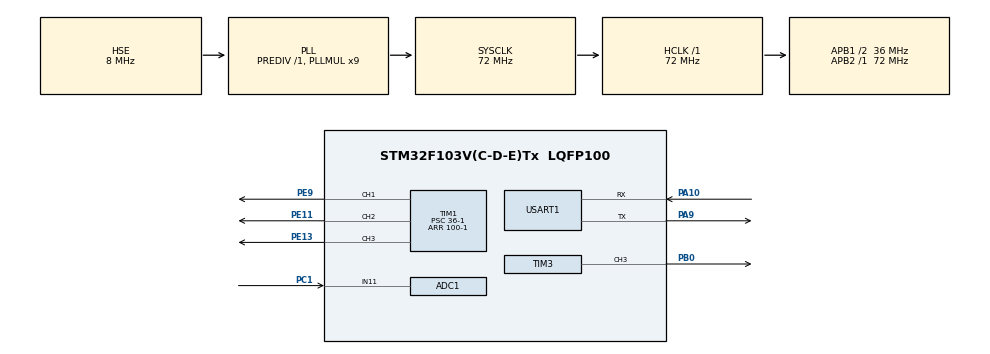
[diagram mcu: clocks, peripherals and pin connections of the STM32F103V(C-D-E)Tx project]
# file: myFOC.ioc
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ADC1.Channel-0\#ChannelRegularConversion=ADC_CHANNEL_11
ADC1.ContinuousConvMode=ENABLE
ADC1.NbrOfConversionFlag=1
ADC1.Rank-0\#ChannelRegularConversion=1
ADC1.SamplingTime-0\#ChannelRegularConversion=ADC_SAMPLETIME_1CYCLE_5
ADC1.master=1
Mcu.Family=STM32F1
Mcu.Name=STM32F103V(C-D-E)Tx
Mcu.Package=LQFP100
NVIC.PriorityGroup=NVIC_PRIORITYGROUP_4
OSC_IN.Mode=HSE-External-Oscillator
OSC_IN.Signal=RCC_OSC_IN
OSC_OUT.Mode=HSE-External-Oscillator
OSC_OUT.Signal=RCC_OSC_OUT
PA10.Mode=Asynchronous
PA10.Signal=USART1_RX
PA13.Mode=Serial_Wire
PA13.Signal=SYS_JTMS-SWDIO
PA14.Mode=Serial_Wire
PA14.Signal=SYS_JTCK-SWCLK
PA9.Mode=Asynchronous
PA9.Signal=USART1_TX
PB0.Signal=S_TIM3_CH3
PC1.Signal=ADCx_IN11
PE11.Signal=S_TIM1_CH2
PE13.Signal=S_TIM1_CH3
PE9.Signal=S_TIM1_CH1
ProjectManager.HeapSize=0x200
ProjectManager.StackSize=0x400
ProjectManager.TargetToolchain=STM32CubeIDE
RCC.ADCPresc=RCC_ADCPCLK2_DIV6
RCC.AHBFreq_Value=72000000
RCC.APB1CLKDivider=RCC_HCLK_DIV2
RCC.APB1Freq_Value=36000000
RCC.APB1TimFreq_Value=72000000
RCC.APB2Freq_Value=72000000
RCC.APB2TimFreq_Value=72000000
RCC.HCLKFreq_Value=72000000
RCC.PLLMUL=RCC_PLL_MUL9
RCC.PLLSourceVirtual=RCC_PLLSOURCE_HSE
RCC.SYSCLKFreq_VALUE=72000000
RCC.SYSCLKSource=RCC_SYSCLKSOURCE_PLLCLK
RCC.USBFreq_Value=72000000
RealThread.RT-Thread.3.1.5.RTOSJjkernel=true
RealThread.RT-Thread.3.1.5.RTOSJjshell=true
SH.ADCx_IN11.0=ADC1_IN11,IN11
SH.S_TIM1_CH1.0=TIM1_CH1,PWM Generation1 CH1
SH.S_TIM1_CH2.0=TIM1_CH2,Output Compare2 CH2
SH.S_TIM1_CH3.0=TIM1_CH3,Output Compare3 CH3
SH.S_TIM3_CH3.0=TIM3_CH3,PWM Generation3 CH3
TIM1.AutoReloadPreload=TIM_AUTORELOAD_PRELOAD_ENABLE
TIM1.Channel-Output\ Compare2\ CH2=TIM_CHANNEL_2
TIM1.Channel-Output\ Compare3\ CH3=TIM_CHANNEL_3
TIM1.Channel-PWM\ Generation1\ CH1=TIM_CHANNEL_1
TIM1.Period=100-1
TIM1.Prescaler=36-1
TIM3.AutoReloadPreload=TIM_AUTORELOAD_PRELOAD_ENABLE
TIM3.Channel-PWM\ Generation3\ CH3=TIM_CHANNEL_3
TIM3.Period=1000
TIM3.Prescaler=72-1
USART1.VirtualMode=VM_ASYNC
VP_RealThread.RT-Thread_VS_RTOSJjkernel_3.1.5_3.1.5.Mode=RTOSJjkernel
VP_RealThread.RT-Thread_VS_RTOSJjshell_3.1.5_3.1.5.Mode=RTOSJjshell
board=custom

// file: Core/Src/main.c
/* USER CODE BEGIN Header */
/**
  ******************************************************************************
  * @file           : main.c
  * @brief          : Main program body
  ******************************************************************************
  * @attention
  *
  * Copyright (c) 2024 STMicroelectronics.
  * All rights reserved.
  *
  * This software is licensed under terms that can be found in the LICENSE file
  * in the root directory of this software component.
  * If no LICENSE file comes with this software, it is provided AS-IS.
  *
  ******************************************************************************
  */
/* USER CODE END Header */
#include "main.h"
#include "adc.h"
#include "tim.h"
#include "usart.h"
#include "gpio.h"

/* USER CODE BEGIN Includes */
#include "rtthread.h"
#include "rt_mailbox.h"
/* USER CODE END Includes */

void SystemClock_Config(void);

int main(void) {

    /* MCU Configuration--------------------------------------------------------*/

    /* Reset of all peripherals, Initializes the Flash interface and the Systick. */
    HAL_Init();

    /* Configure the system clock */
    SystemClock_Config();

    /* Initialize all configured peripherals */
    MX_GPIO_Init();
    MX_TIM1_Init();
    MX_TIM3_Init();
    MX_USART1_UART_Init();
    MX_ADC1_Init();

    /* Infinite loop */
    /* USER CODE BEGIN WHILE */
    while (1) {
//        rt_kprintf("ok\n");
        rt_thread_delay(1000);
        /* USER CODE END WHILE */

    }
}

void SystemClock_Config(void) {
    RCC_OscInitTypeDef RCC_OscInitStruct = {0};
    RCC_ClkInitTypeDef RCC_ClkInitStruct = {0};
    RCC_PeriphCLKInitTypeDef PeriphClkInit = {0};

    /** Initializes the RCC Oscillators according to the specified parameters
    * in the RCC_OscInitTypeDef structure.
    */
    RCC_OscInitStruct.OscillatorType = RCC_OSCILLATORTYPE_HSE;
    RCC_OscInitStruct.HSEState = RCC_HSE_ON;
    RCC_OscInitStruct.HSEPredivValue = RCC_HSE_PREDIV_DIV1;
    RCC_OscInitStruct.HSIState = RCC_HSI_ON;
    RCC_OscInitStruct.PLL.PLLState = RCC_PLL_ON;
    RCC_OscInitStruct.PLL.PLLSource = RCC_PLLSOURCE_HSE;
    RCC_OscInitStruct.PLL.PLLMUL = RCC_PLL_MUL9;
    if (HAL_RCC_OscConfig(&RCC_OscInitStruct) != HAL_OK) {
        Error_Handler();
    }

    /** Initializes the CPU, AHB and APB buses clocks
    */
    RCC_ClkInitStruct.ClockType = RCC_CLOCKTYPE_HCLK | RCC_CLOCKTYPE_SYSCLK
                                  | RCC_CLOCKTYPE_PCLK1 | RCC_CLOCKTYPE_PCLK2;
    RCC_ClkInitStruct.SYSCLKSource = RCC_SYSCLKSOURCE_PLLCLK;
    RCC_ClkInitStruct.AHBCLKDivider = RCC_SYSCLK_DIV1;
    RCC_ClkInitStruct.APB1CLKDivider = RCC_HCLK_DIV2;
    RCC_ClkInitStruct.APB2CLKDivider = RCC_HCLK_DIV1;

    if (HAL_RCC_ClockConfig(&RCC_ClkInitStruct, FLASH_LATENCY_2) != HAL_OK) {
        Error_Handler();
    }
    PeriphClkInit.PeriphClockSelection = RCC_PERIPHCLK_ADC;
    PeriphClkInit.AdcClockSelection = RCC_ADCPCLK2_DIV6;
    if (HAL_RCCEx_PeriphCLKConfig(&PeriphClkInit) != HAL_OK) {
        Error_Handler();
    }
}

void Error_Handler(void) {
    __disable_irq();
    while (1) {
    }
}
